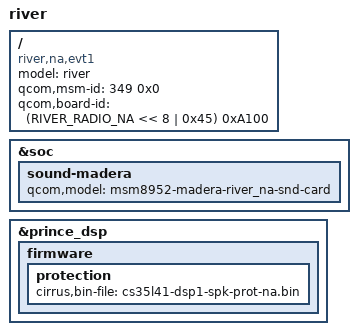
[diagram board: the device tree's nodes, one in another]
/* Copyright (c) 2018, The Linux Foundation. All rights reserved.
 *
 * This program is free software; you can redistribute it and/or modify
 * it under the terms of the GNU General Public License version 2 and
 * only version 2 as published by the Free Software Foundation.
 *
 * This program is distributed in the hope that it will be useful,
 * but WITHOUT ANY WARRANTY; without even the implied warranty of
 * MERCHANTABILITY or FITNESS FOR A PARTICULAR PURPOSE.  See the
 * GNU General Public License for more details.
 */

/dts-v1/;
/plugin/;

#include <dt-bindings/clock/msm-clocks-8953.h>

#include "sdm632-river-common-overlay.dtsi"

/ {
	model = "river";
	compatible = "river,na,evt1";
	qcom,msm-id = <349 0x0>;
	qcom,board-id = <(RIVER_RADIO_NA << 8 | 0x45) 0xA100>;
};

/*
 * River NA HW rev EVT0 specific changes go here
 */

&soc {
	sound-madera {
		qcom,model = "msm8952-madera-river_na-snd-card";
	};
};

&prince_dsp {
	firmware {
		protection {
			cirrus,bin-file = "cs35l41-dsp1-spk-prot-na.bin";
		};
	};
};
